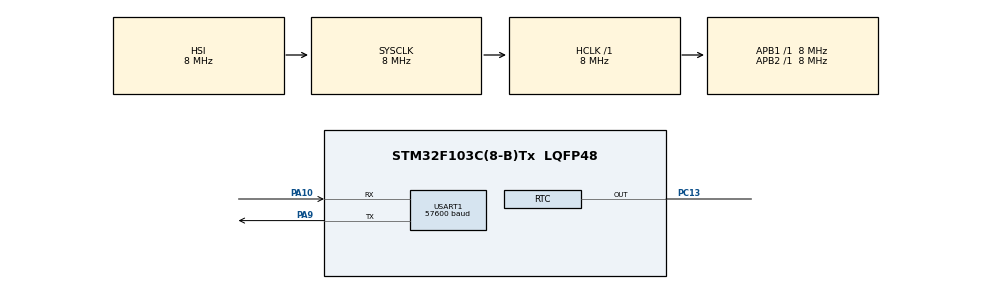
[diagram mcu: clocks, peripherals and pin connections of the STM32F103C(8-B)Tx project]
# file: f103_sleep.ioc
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Mcu.Family=STM32F1
PA10.Mode=Asynchronous
USART1.BaudRate=57600
VP_RTC_VS_RTC_Activate.Mode=RTC_Enabled
PC13-TAMPER-RTC.Signal=RTC_OUT
ProjectManager.StackSize=0x400
NVIC.RTC_IRQn=true\:0\:0\:false\:false\:true\:true\:true
PA13.Signal=SYS_JTMS-SWDIO
PA9.Mode=Asynchronous
ProjectManager.TargetToolchain=STM32CubeIDE
RCC.HCLKFreq_Value=8000000
RCC.APB2TimFreq_Value=8000000
PA9.Signal=USART1_TX
RCC.USBFreq_Value=24000000
RCC.AHBFreq_Value=8000000
board=custom
RCC.PLLMUL=RCC_PLL_MUL6
RTC.Hours_A-RTC\ OUT=1
PC13-TAMPER-RTC.Mode=RTC OUT
RCC.APB2Freq_Value=8000000
PA14.Mode=Serial_Wire
RTC.AsynchPrediv=RTC_AUTO_1_SECOND
PA13.Mode=Serial_Wire
NVIC.RTC_Alarm_IRQn=true\:0\:0\:false\:false\:true\:true\:true
Mcu.Name=STM32F103C(8-B)Tx
RCC.SYSCLKFreq_VALUE=8000000
RTC.Hours=1
Mcu.Package=LQFP48
RCC.HSEDivPLL=RCC_HSE_PREDIV_DIV2
USART1.VirtualMode=VM_ASYNC
PA10.Signal=USART1_RX
PA14.Signal=SYS_JTCK-SWCLK
VP_RTC_VS_RTC_Calendar.Mode=RTC_Calendar
ProjectManager.HeapSize=0x200
NVIC.PriorityGroup=NVIC_PRIORITYGROUP_4
RCC.APB1TimFreq_Value=8000000
RTC.AutoPrediv=RTC_AUTO_1_SECOND
RCC.APB1Freq_Value=8000000
RTC.Seconds_A-RTC\ OUT=10
RTC.OutPut=RTC_OUTPUTSOURCE_ALARM

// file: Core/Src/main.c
/* USER CODE BEGIN Header */
/**
  ******************************************************************************
  * @file           : main.c
  * @brief          : Main program body
  ******************************************************************************
  * @attention
  *
  * <h2><center>&copy; Copyright (c) 2021 STMicroelectronics.
  * All rights reserved.</center></h2>
  *
  * This software component is licensed by ST under BSD 3-Clause license,
  * the "License"; You may not use this file except in compliance with the
  * License. You may obtain a copy of the License at:
  *                        opensource.org/licenses/BSD-3-Clause
  *
  ******************************************************************************
  */
/* USER CODE END Header */
#include "main.h"

/* USER CODE BEGIN Includes */
#include "stdio.h"
#include "string.h"
/* USER CODE END Includes */

RTC_HandleTypeDef hrtc;

UART_HandleTypeDef huart1;

void SystemClock_Config(void);
static void MX_GPIO_Init(void);
static void MX_USART1_UART_Init(void);
static void MX_RTC_Init(void);

/* USER CODE BEGIN 0 */
static char UART_msg_TX[50]; // массив для формирования сообщений для вывода по UART
/* USER CODE END 0 */

int main(void)
{
  /* USER CODE BEGIN 1 */
	 RTC_TimeTypeDef sTime;
	 RTC_AlarmTypeDef sAlarm;
  /* USER CODE END 1 */

  /* MCU Configuration--------------------------------------------------------*/

  /* Reset of all peripherals, Initializes the Flash interface and the Systick. */
  HAL_Init();

  /* Configure the system clock */
  SystemClock_Config();

  /* Initialize all configured peripherals */
  MX_GPIO_Init();
  MX_USART1_UART_Init();
  MX_RTC_Init();
  /* USER CODE BEGIN 2 */
  sprintf (UART_msg_TX,"sleep_mode_start\r\n");
  HAL_UART_Transmit(&huart1, (unsigned char*)UART_msg_TX, strlen(UART_msg_TX), 0x1000);
  HAL_PWR_EnterSLEEPMode(PWR_MAINREGULATOR_ON, PWR_SLEEPENTRY_WFI);
  /* USER CODE END 2 */

  /* Infinite loop */
  while (1)
  {

    /* USER CODE BEGIN 3 */
	  sprintf (UART_msg_TX,"sleep...\r\n");
	  HAL_UART_Transmit(&huart1, (unsigned char*)UART_msg_TX, strlen(UART_msg_TX), 0x1000);
	  HAL_SuspendTick(); //разрешение прерывания по достижению 0 таймера  SysTick. Перед переходом в спящий режим SLEEP целесообразно бит TICKINT сбросить.
	  HAL_PWR_EnterSLEEPMode(PWR_MAINREGULATOR_ON, PWR_SLEEPENTRY_WFI);
	  HAL_ResumeTick();
	  sTime.Hours = 1;
	  sTime.Minutes = 0;
	  sTime.Seconds = 0;
	  if (HAL_RTC_SetTime(&hrtc, &sTime, RTC_FORMAT_BIN) != HAL_OK)
	   {
	     Error_Handler();
	   }
	  sAlarm.AlarmTime.Hours = 1;
	  sAlarm.AlarmTime.Minutes = 0;
	  sAlarm.AlarmTime.Seconds = 5;
	  sAlarm.Alarm = RTC_ALARM_A;
	  if (HAL_RTC_SetAlarm_IT(&hrtc, &sAlarm, RTC_FORMAT_BIN) != HAL_OK)
	    {
	      Error_Handler();
	    }
	  sprintf (UART_msg_TX,"wake up!\r\n");
	  HAL_UART_Transmit(&huart1, (unsigned char*)UART_msg_TX, strlen(UART_msg_TX), 0x1000);
  }
  /* USER CODE END 3 */
}

void SystemClock_Config(void)
{
  RCC_OscInitTypeDef RCC_OscInitStruct = {0};
  RCC_ClkInitTypeDef RCC_ClkInitStruct = {0};
  RCC_PeriphCLKInitTypeDef PeriphClkInit = {0};

  /** Initializes the RCC Oscillators according to the specified parameters
  * in the RCC_OscInitTypeDef structure.
  */
  RCC_OscInitStruct.OscillatorType = RCC_OSCILLATORTYPE_HSI|RCC_OSCILLATORTYPE_LSI;
  RCC_OscInitStruct.HSIState = RCC_HSI_ON;
  RCC_OscInitStruct.HSICalibrationValue = RCC_HSICALIBRATION_DEFAULT;
  RCC_OscInitStruct.LSIState = RCC_LSI_ON;
  RCC_OscInitStruct.PLL.PLLState = RCC_PLL_NONE;
  if (HAL_RCC_OscConfig(&RCC_OscInitStruct) != HAL_OK)
  {
    Error_Handler();
  }
  /** Initializes the CPU, AHB and APB buses clocks
  */
  RCC_ClkInitStruct.ClockType = RCC_CLOCKTYPE_HCLK|RCC_CLOCKTYPE_SYSCLK
                              |RCC_CLOCKTYPE_PCLK1|RCC_CLOCKTYPE_PCLK2;
  RCC_ClkInitStruct.SYSCLKSource = RCC_SYSCLKSOURCE_HSI;
  RCC_ClkInitStruct.AHBCLKDivider = RCC_SYSCLK_DIV1;
  RCC_ClkInitStruct.APB1CLKDivider = RCC_HCLK_DIV1;
  RCC_ClkInitStruct.APB2CLKDivider = RCC_HCLK_DIV1;

  if (HAL_RCC_ClockConfig(&RCC_ClkInitStruct, FLASH_LATENCY_0) != HAL_OK)
  {
    Error_Handler();
  }
  PeriphClkInit.PeriphClockSelection = RCC_PERIPHCLK_RTC;
  PeriphClkInit.RTCClockSelection = RCC_RTCCLKSOURCE_LSI;
  if (HAL_RCCEx_PeriphCLKConfig(&PeriphClkInit) != HAL_OK)
  {
    Error_Handler();
  }
}

static void MX_RTC_Init(void)
{

  RTC_TimeTypeDef sTime = {0};
  RTC_DateTypeDef DateToUpdate = {0};
  RTC_AlarmTypeDef sAlarm = {0};

  /** Initialize RTC Only
  */
  hrtc.Instance = RTC;
  hrtc.Init.AsynchPrediv = RTC_AUTO_1_SECOND;
  hrtc.Init.OutPut = RTC_OUTPUTSOURCE_ALARM;
  if (HAL_RTC_Init(&hrtc) != HAL_OK)
  {
    Error_Handler();
  }

  /** Initialize RTC and set the Time and Date
  */
  sTime.Hours = 0x1;
  sTime.Minutes = 0x0;
  sTime.Seconds = 0x0;

  if (HAL_RTC_SetTime(&hrtc, &sTime, RTC_FORMAT_BCD) != HAL_OK)
  {
    Error_Handler();
  }
  DateToUpdate.WeekDay = RTC_WEEKDAY_MONDAY;
  DateToUpdate.Month = RTC_MONTH_JANUARY;
  DateToUpdate.Date = 0x1;
  DateToUpdate.Year = 0x0;

  if (HAL_RTC_SetDate(&hrtc, &DateToUpdate, RTC_FORMAT_BCD) != HAL_OK)
  {
    Error_Handler();
  }
  /** Enable the Alarm A
  */
  sAlarm.AlarmTime.Hours = 0x1;
  sAlarm.AlarmTime.Minutes = 0x0;
  sAlarm.AlarmTime.Seconds = 0x10;
  sAlarm.Alarm = RTC_ALARM_A;
  if (HAL_RTC_SetAlarm_IT(&hrtc, &sAlarm, RTC_FORMAT_BCD) != HAL_OK)
  {
    Error_Handler();
  }

}

static void MX_USART1_UART_Init(void)
{

  huart1.Instance = USART1;
  huart1.Init.BaudRate = 57600;
  huart1.Init.WordLength = UART_WORDLENGTH_8B;
  huart1.Init.StopBits = UART_STOPBITS_1;
  huart1.Init.Parity = UART_PARITY_NONE;
  huart1.Init.Mode = UART_MODE_TX_RX;
  huart1.Init.HwFlowCtl = UART_HWCONTROL_NONE;
  huart1.Init.OverSampling = UART_OVERSAMPLING_16;
  if (HAL_UART_Init(&huart1) != HAL_OK)
  {
    Error_Handler();
  }

}

static void MX_GPIO_Init(void)
{

  /* GPIO Ports Clock Enable */
  __HAL_RCC_GPIOC_CLK_ENABLE();
  __HAL_RCC_GPIOA_CLK_ENABLE();

}

void Error_Handler(void)
{
  __disable_irq();
  while (1)
  {
  }
}

/************************ (C) COPYRIGHT STMicroelectronics *****END OF FILE****/
